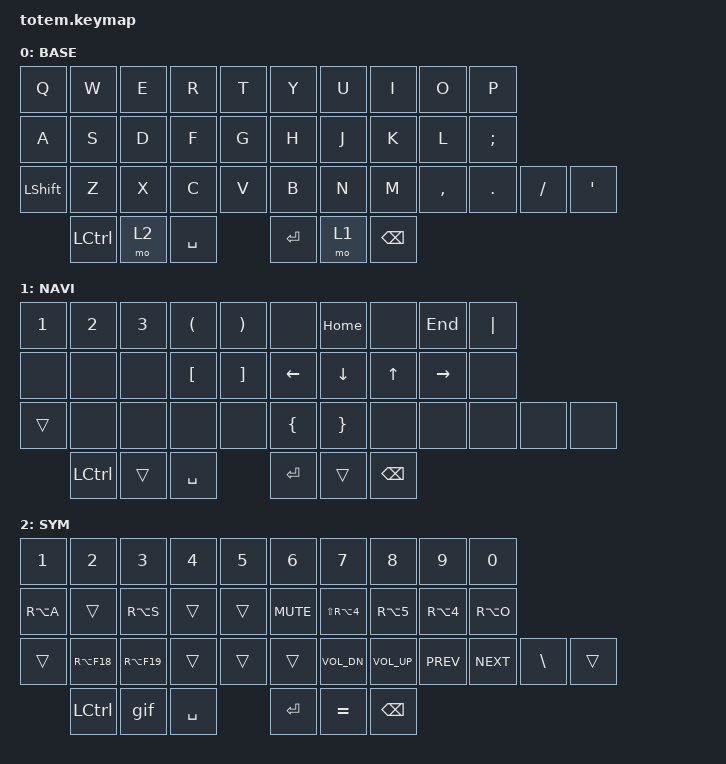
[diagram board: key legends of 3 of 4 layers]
#include <behaviors.dtsi>
#include <dt-bindings/zmk/keys.h>
#include <dt-bindings/zmk/bt.h>
#include <dt-bindings/zmk/outputs.h>

#define BASE 0
#define NAV  1
#define SYM  2
#define ADJ  3
#define TVP1 4
#define TVP2 5

&mt {
    quick-tap-ms = <100>;
    global-quick-tap;
    flavor = "tap-preferred";
    tapping-term-ms = <170>;
};

 / {
    combos {
        compatible = "zmk,combos";

        /* J + K -> ESC (key positions 16 & 17) */
        combo_jk_esc {
            timeout-ms = <50>;
            key-positions = <16 17>;
            bindings = <&kp ESC>;
        };

        /* D + F -> TAB (key positions 12 & 13) */
        combo_df_tab {
            timeout-ms = <50>;
            key-positions = <12 13>;
            bindings = <&kp TAB>;
        };

        /* SPACE + ENTER -> momentary ADJ while both are held */
        combo_space_enter_adjust {
            timeout-ms = <120>;
            slow-release;
            key-positions = <34 35>;
            bindings = <&mo ADJ>;
        };
    };

    macros {
        gif: gif {
            label = "giphy";
            compatible = "zmk,behavior-macro";
            #binding-cells = <0>;
            bindings =
                <&macro_press &kp LSHFT>,
                <&macro_tap &kp N2>,
                <&macro_release &kp LSHFT>,
                <&macro_tap &kp G &kp I &kp F>;
        };
    };

    keymap {
        compatible = "zmk,keymap";

        base_layer {
            label = "BASE";
            bindings = <
                &kp Q       &kp W       &kp E       &kp R       &kp T           &kp Y       &kp U       &kp I       &kp O       &kp P
                &kp A       &kp S       &kp D       &kp F       &kp G           &kp H       &kp J       &kp K       &kp L       &kp SEMI
                &kp LSHFT   &kp Z       &kp X       &kp C       &kp V           &kp B       &kp N       &kp M       &kp COMMA   &kp DOT     &kp SLASH   &kp QUOT
                                 &kp LCTRL     &mo 2       &kp SPACE            &kp RET     &mo 1         &kp BSPC
            >;
        };

        nav_layer {
            label = "NAVI";
            bindings = <
                &kp N1      &kp N2      &kp N3      &kp LPAR    &kp RPAR        &none       &kp HOME    &none       &kp END     &kp PIPE
                &none       &none       &none       &kp LBKT    &kp RBKT        &kp LEFT    &kp DOWN    &kp UP      &kp RIGHT   &none
                &trans      &none       &none       &none       &none           &kp LBRC    &kp RBRC    &none       &none       &none       &none       &none
                                   &kp LCTRL   &trans       &kp SPACE          &kp RET     &trans       &kp BSPC
            >;
        };

        sim_layer {
            label = "SYM";
            bindings = <
                &kp N1      &kp N2      &kp N3      &kp N4      &kp N5        &kp N6      &kp N7      &kp N8      &kp N9      &kp N0
                &kp RA(A)   &trans      &kp RA(S)   &trans      &trans         &kp C_MUTE  &kp LS(RA(N4)) &kp RA(N5) &kp RA(N4) &kp RA(O)
                &trans      &kp RA(F18) &kp RA(F19) &trans      &trans         &trans      &kp C_VOL_DN  &kp C_VOL_UP &kp C_PREV &kp C_NEXT  &kp BSLH   &trans
                                                &kp LCTRL   &gif        &kp SPACE        &kp ENTER   &kp EQUAL   &kp BSPC
            >;
        };

        adjust_layer {
            label = "ADJ";
            bindings = <
                &kp F1     &kp F2      &kp F3      &kp F4      &kp F5          &kp F6      &kp F7      &kp F8      &kp F9      &kp F10     
                &none      &none       &none       &none      &none           &none       &none       &none       &kp F11     &kp F12     &none
                &none      &out OUT_BLE &bt BT_NXT  &bt BT_PRV  &bt BT_CLR      &none       &none       &none       &none       &none      
                                         &trans      &trans      &trans         &trans      &trans      &trans
            >;
        };
    };
};
